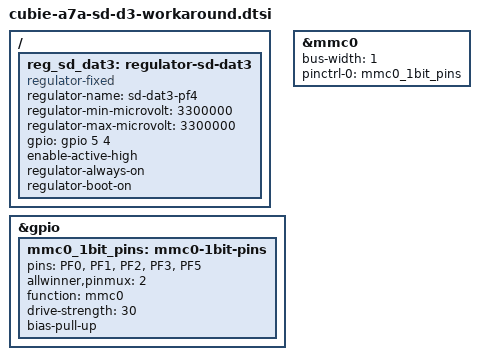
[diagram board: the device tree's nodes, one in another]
// SPDX-License-Identifier: (GPL-2.0-only OR MIT)
/*
 * Cubie A7A board workaround (2026-11-11): microSD DAT3 (SDC0-D3, PF4)
 * leaks to ground on the board under test. As an input with the internal
 * pull-up PF4 reads low with or without a card; driven as a GPIO output
 * high it reads back high. A card that sees DAT3 (CD/DAT3) low at CMD0
 * enters SPI mode and stops answering, so the slot only works with PF4
 * driven high and the bus on D0 alone. bt0 and EDK2 do the same (PF4 a
 * GPIO output high, 1-bit bus); this keeps Linux from undoing it.
 *
 * - mmc0 runs 1-bit and its pin state no longer contains PF4. The SoC's
 *   mmc0_pins group (PF0..PF5) is deleted: /omit-if-no-ref/ does not drop
 *   it from a DTB built with -@ (its label stays in __symbols__), and no
 *   node or overlay may mux PF4 to SDC0.
 * - PF4 is claimed and driven high by an always-on fixed regulator, the
 *   same mechanism as the PM0/PM1 Wi-Fi enables in cubie-a7a-board-io.dtsi
 *   (proven on this board). regulator-boot-on makes reg-fixed-voltage
 *   request the line GPIOD_OUT_HIGH (the A733 pinctrl sets the data bit
 *   before switching to output), so PF4 never goes low; firmware already
 *   left it high, and the pin controller's probe does not touch it.
 *
 * Not used, on purpose:
 * - a gpio-hog on &gpio: since Linux 7.1 gpiochip_add_hog() takes the raw
 *   first cell as the line offset, so a 3-cell <5 4 0> hog lands on the
 *   wrong line and fails the whole pin controller probe (first boot,
 *   2026-11-11; the PC7 hog was removed for the same reason).
 * - "output-high" in a pinctrl state: the sunxi pinctrl DT parser
 *   (sunxi_pctrl_build_pin_config) only takes drive-strength and bias, so
 *   the property would be ignored.
 * - a GPIO-function pin state without a driver owning the line: the data
 *   latch would not be set by pinctrl and the line could drive low.
 *
 * Remove this file once the board is repaired (or for a board without the
 * fault) to get the 4-bit bus back.
 */

/ {
	reg_sd_dat3: regulator-sd-dat3 {
		compatible = "regulator-fixed";
		regulator-name = "sd-dat3-pf4";
		regulator-min-microvolt = <3300000>;
		regulator-max-microvolt = <3300000>;
		gpio = <&gpio 5 4 GPIO_ACTIVE_HIGH>; /* PF4 = SDC0-D3 */
		enable-active-high;
		regulator-always-on;
		regulator-boot-on;
	};
};

&gpio {
	mmc0_1bit_pins: mmc0-1bit-pins {
		/* PF0 D1, PF1 D0, PF2 CLK, PF3 CMD, PF5 D2; not PF4 (D3) */
		pins = "PF0", "PF1", "PF2", "PF3", "PF5";
		allwinner,pinmux = <2>;
		function = "mmc0";
		drive-strength = <30>;
		bias-pull-up;
	};
};

/delete-node/ &mmc0_pins;

&mmc0 {
	bus-width = <1>;
	pinctrl-names = "default";
	pinctrl-0 = <&mmc0_1bit_pins>;
};
